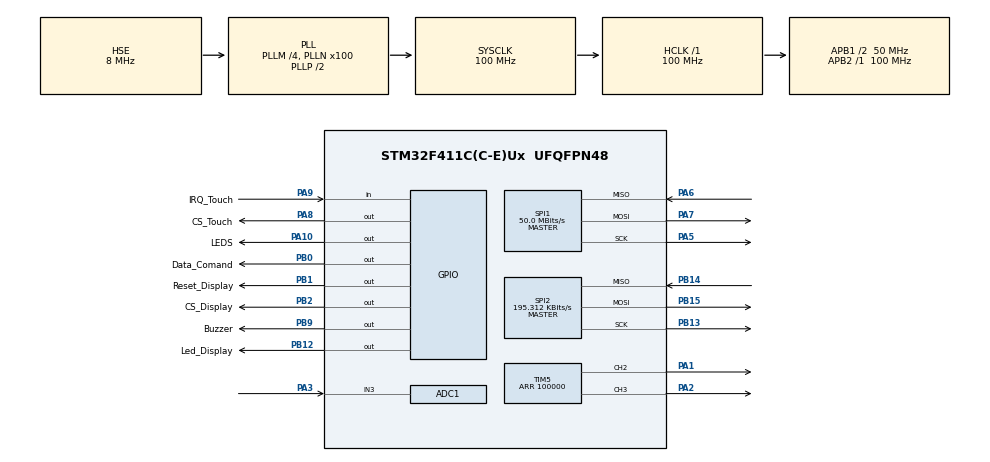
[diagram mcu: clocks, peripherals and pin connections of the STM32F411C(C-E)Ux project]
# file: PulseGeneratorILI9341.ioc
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ADC1.Channel-0\#ChannelRegularConversion=ADC_CHANNEL_3
ADC1.ClockPrescaler=ADC_CLOCK_SYNC_PCLK_DIV6
ADC1.ContinuousConvMode=ENABLE
ADC1.DMAContinuousRequests=ENABLE
ADC1.ExternalTrigConv=ADC_SOFTWARE_START
ADC1.InjNumberOfConversion=0
ADC1.NbrOfConversion=1
ADC1.NbrOfConversionFlag=1
ADC1.Rank-0\#ChannelRegularConversion=1
ADC1.SamplingTime-0\#ChannelRegularConversion=ADC_SAMPLETIME_480CYCLES
ADC1.master=1
Dma.ADC1.0.Direction=DMA_PERIPH_TO_MEMORY
Dma.ADC1.0.FIFOMode=DMA_FIFOMODE_DISABLE
Dma.ADC1.0.Instance=DMA2_Stream0
Dma.ADC1.0.MemDataAlignment=DMA_MDATAALIGN_HALFWORD
Dma.ADC1.0.MemInc=DMA_MINC_ENABLE
Dma.ADC1.0.Mode=DMA_CIRCULAR
Dma.ADC1.0.PeriphDataAlignment=DMA_PDATAALIGN_HALFWORD
Dma.ADC1.0.PeriphInc=DMA_PINC_DISABLE
Dma.ADC1.0.Priority=DMA_PRIORITY_LOW
Dma.Request0=ADC1
Mcu.Family=STM32F4
Mcu.Name=STM32F411C(C-E)Ux
Mcu.Package=UFQFPN48
NVIC.PriorityGroup=NVIC_PRIORITYGROUP_4
NVIC.TIM5_IRQn=true\:0\:0\:false\:false\:true\:true\:true\:true
PA1.Signal=S_TIM5_CH2
PA10.GPIO_Label=LEDS
PA10.Signal=GPIO_Output
PA13.Mode=Serial_Wire
PA13.Signal=SYS_JTMS-SWDIO
PA14.Mode=Serial_Wire
PA14.Signal=SYS_JTCK-SWCLK
PA2.Signal=S_TIM5_CH3
PA3.Signal=ADCx_IN3
PA5.Mode=Full_Duplex_Master
PA5.Signal=SPI1_SCK
PA6.Mode=Full_Duplex_Master
PA6.Signal=SPI1_MISO
PA7.Mode=Full_Duplex_Master
PA7.Signal=SPI1_MOSI
PA8.GPIO_Label=CS_Touch
PA8.Signal=GPIO_Output
PA9.GPIO_Label=IRQ_Touch
PA9.Signal=GPIO_Input
PB0.GPIO_Label=Data_Comand
PB0.Signal=GPIO_Output
PB1.GPIO_Label=Reset_Display
PB1.Signal=GPIO_Output
PB12.GPIO_Label=Led_Display
PB12.Signal=GPIO_Output
PB13.Mode=Full_Duplex_Master
PB13.Signal=SPI2_SCK
PB14.Mode=Full_Duplex_Master
PB14.Signal=SPI2_MISO
PB15.Mode=Full_Duplex_Master
PB15.Signal=SPI2_MOSI
PB2.GPIO_Label=CS_Display
PB2.Signal=GPIO_Output
PB9.GPIO_Label=Buzzer
PB9.Signal=GPIO_Output
PH0\ -\ OSC_IN.Mode=HSE-External-Oscillator
PH0\ -\ OSC_IN.Signal=RCC_OSC_IN
PH1\ -\ OSC_OUT.Mode=HSE-External-Oscillator
PH1\ -\ OSC_OUT.Signal=RCC_OSC_OUT
ProjectManager.HeapSize=0x200
ProjectManager.StackSize=0x400
ProjectManager.TargetToolchain=STM32CubeIDE
RCC.48MHZClocksFreq_Value=50000000
RCC.AHBFreq_Value=100000000
RCC.APB1CLKDivider=RCC_HCLK_DIV2
RCC.APB1Freq_Value=50000000
RCC.APB1TimFreq_Value=100000000
RCC.APB2Freq_Value=100000000
RCC.APB2TimFreq_Value=100000000
RCC.CortexFreq_Value=100000000
RCC.HCLKFreq_Value=100000000
RCC.HSE_VALUE=8000000
RCC.HSI_VALUE=16000000
RCC.LSE_VALUE=32768
RCC.PLLM=4
RCC.PLLN=100
RCC.PLLSourceVirtual=RCC_PLLSOURCE_HSE
RCC.SYSCLKFreq_VALUE=100000000
RCC.SYSCLKSource=RCC_SYSCLKSOURCE_PLLCLK
RCC.VCOOutputFreq_Value=200000000
SH.ADCx_IN3.0=ADC1_IN3,IN3
SH.S_TIM5_CH2.0=TIM5_CH2,PWM Generation2 CH2
SH.S_TIM5_CH3.0=TIM5_CH3,PWM Generation3 CH3
SPI1.BaudRatePrescaler=SPI_BAUDRATEPRESCALER_2
SPI1.CalculateBaudRate=50.0 MBits/s
SPI1.Direction=SPI_DIRECTION_2LINES
SPI1.Mode=SPI_MODE_MASTER
SPI1.VirtualType=VM_MASTER
SPI2.BaudRatePrescaler=SPI_BAUDRATEPRESCALER_256
SPI2.CalculateBaudRate=195.312 KBits/s
SPI2.Direction=SPI_DIRECTION_2LINES
SPI2.Mode=SPI_MODE_MASTER
SPI2.VirtualType=VM_MASTER
TIM5.AutoReloadPreload=TIM_AUTORELOAD_PRELOAD_ENABLE
TIM5.Channel-PWM\ Generation2\ CH2=TIM_CHANNEL_2
TIM5.Channel-PWM\ Generation3\ CH3=TIM_CHANNEL_3
TIM5.Period=100000
TIM5.Pulse-PWM\ Generation2\ CH2=25000
TIM5.Pulse-PWM\ Generation3\ CH3=2100
TIM5.TIM_MasterSlaveMode=TIM_MASTERSLAVEMODE_DISABLE
board=custom

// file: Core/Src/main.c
/* USER CODE BEGIN Header */
/**
  ******************************************************************************
  * @file           : main.c
  * @brief          : Main program body
  ******************************************************************************
  * @attention
  *
  * Copyright (c) 2023 STMicroelectronics.
  * All rights reserved.
  *
  * This software is licensed under terms that can be found in the LICENSE file
  * in the root directory of this software component.
  * If no LICENSE file comes with this software, it is provided AS-IS.
  *
  ******************************************************************************
  */
/* USER CODE END Header */
#include "main.h"

ADC_HandleTypeDef hadc1;
DMA_HandleTypeDef hdma_adc1;

SPI_HandleTypeDef hspi1;
SPI_HandleTypeDef hspi2;

TIM_HandleTypeDef htim5;

/* USER CODE BEGIN PV */
uint16_t adcBuf [FILTRADC] = {0};
//uint32_t * ptrBuf = adcBuf;
/* USER CODE END PV */

void SystemClock_Config(void);
static void MX_GPIO_Init(void);
static void MX_DMA_Init(void);
static void MX_SPI1_Init(void);
static void MX_SPI2_Init(void);
static void MX_TIM5_Init(void);
static void MX_ADC1_Init(void);

/* USER CODE BEGIN 0 */

/*void HAL_GPIO_EXTI_Callback(uint16_t GPIO_Pin){
}*/

/* USER CODE END 0 */

int main(void)
{
  /* USER CODE BEGIN 1 */
  //SYSCFG->MEMRMP = 0x3;    // для запуска из SRAM
  /* USER CODE END 1 */

  /* MCU Configuration--------------------------------------------------------*/

  /* Reset of all peripherals, Initializes the Flash interface and the Systick. */
  HAL_Init();

  /* Configure the system clock */
  SystemClock_Config();

  /* Initialize all configured peripherals */
  MX_GPIO_Init();
  MX_DMA_Init();
  MX_SPI1_Init();
  MX_SPI2_Init();
  MX_TIM5_Init();
  MX_ADC1_Init();
  /* USER CODE BEGIN 2 */
  SET_BIT(TIM5->CCER, TIM_CCER_CC2E);                     // включим выходы таймера на ноги МК
  SET_BIT(TIM5->CCER, TIM_CCER_CC3E);                     // включим выходы таймера на ноги МК
  CLEAR_BIT(TIM5->CCMR1, TIM_CCMR1_OC2M);                 // очистим регистр
  CLEAR_BIT(TIM5->CCMR2, TIM_CCMR2_OC3M);                 // очистим регистр
  SET_BIT(TIM5->CCMR1, 0b100 << TIM_CCMR1_OC2M_Pos);      // ноль на выходе Force inactive level
  SET_BIT(TIM5->CCMR2, 0b100 << TIM_CCMR2_OC3M_Pos);      // ноль на выходе Force inactive level
  HAL_ADC_Start_DMA (&hadc1, (uint32_t *)adcBuf, FILTRADC);      // запустим АЦП
  doWork ();
  /* USER CODE END 2 */

  /* Infinite loop */
  /* USER CODE BEGIN WHILE */
  while (1)
  {
	  Work ();
    /* USER CODE END WHILE */

  }
}

void SystemClock_Config(void)
{
  RCC_OscInitTypeDef RCC_OscInitStruct = {0};
  RCC_ClkInitTypeDef RCC_ClkInitStruct = {0};

  /** Configure the main internal regulator output voltage
  */
  __HAL_RCC_PWR_CLK_ENABLE();
  __HAL_PWR_VOLTAGESCALING_CONFIG(PWR_REGULATOR_VOLTAGE_SCALE1);

  /** Initializes the RCC Oscillators according to the specified parameters
  * in the RCC_OscInitTypeDef structure.
  */
  RCC_OscInitStruct.OscillatorType = RCC_OSCILLATORTYPE_HSE;
  RCC_OscInitStruct.HSEState = RCC_HSE_ON;
  RCC_OscInitStruct.PLL.PLLState = RCC_PLL_ON;
  RCC_OscInitStruct.PLL.PLLSource = RCC_PLLSOURCE_HSE;
  RCC_OscInitStruct.PLL.PLLM = 4;
  RCC_OscInitStruct.PLL.PLLN = 100;
  RCC_OscInitStruct.PLL.PLLP = RCC_PLLP_DIV2;
  RCC_OscInitStruct.PLL.PLLQ = 4;
  if (HAL_RCC_OscConfig(&RCC_OscInitStruct) != HAL_OK)
  {
    Error_Handler();
  }

  /** Initializes the CPU, AHB and APB buses clocks
  */
  RCC_ClkInitStruct.ClockType = RCC_CLOCKTYPE_HCLK|RCC_CLOCKTYPE_SYSCLK
                              |RCC_CLOCKTYPE_PCLK1|RCC_CLOCKTYPE_PCLK2;
  RCC_ClkInitStruct.SYSCLKSource = RCC_SYSCLKSOURCE_PLLCLK;
  RCC_ClkInitStruct.AHBCLKDivider = RCC_SYSCLK_DIV1;
  RCC_ClkInitStruct.APB1CLKDivider = RCC_HCLK_DIV2;
  RCC_ClkInitStruct.APB2CLKDivider = RCC_HCLK_DIV1;

  if (HAL_RCC_ClockConfig(&RCC_ClkInitStruct, FLASH_LATENCY_3) != HAL_OK)
  {
    Error_Handler();
  }
}

static void MX_ADC1_Init(void)
{

  ADC_ChannelConfTypeDef sConfig = {0};

  /** Configure the global features of the ADC (Clock, Resolution, Data Alignment and number of conversion)
  */
  hadc1.Instance = ADC1;
  hadc1.Init.ClockPrescaler = ADC_CLOCK_SYNC_PCLK_DIV6;
  hadc1.Init.Resolution = ADC_RESOLUTION_12B;
  hadc1.Init.ScanConvMode = DISABLE;
  hadc1.Init.ContinuousConvMode = ENABLE;
  hadc1.Init.DiscontinuousConvMode = DISABLE;
  hadc1.Init.ExternalTrigConvEdge = ADC_EXTERNALTRIGCONVEDGE_NONE;
  hadc1.Init.ExternalTrigConv = ADC_SOFTWARE_START;
  hadc1.Init.DataAlign = ADC_DATAALIGN_RIGHT;
  hadc1.Init.NbrOfConversion = 1;
  hadc1.Init.DMAContinuousRequests = ENABLE;
  hadc1.Init.EOCSelection = ADC_EOC_SINGLE_CONV;
  if (HAL_ADC_Init(&hadc1) != HAL_OK)
  {
    Error_Handler();
  }

  /** Configure for the selected ADC regular channel its corresponding rank in the sequencer and its sample time.
  */
  sConfig.Channel = ADC_CHANNEL_3;
  sConfig.Rank = 1;
  sConfig.SamplingTime = ADC_SAMPLETIME_480CYCLES;
  if (HAL_ADC_ConfigChannel(&hadc1, &sConfig) != HAL_OK)
  {
    Error_Handler();
  }

}

static void MX_SPI1_Init(void)
{

  /* SPI1 parameter configuration*/
  hspi1.Instance = SPI1;
  hspi1.Init.Mode = SPI_MODE_MASTER;
  hspi1.Init.Direction = SPI_DIRECTION_2LINES;
  hspi1.Init.DataSize = SPI_DATASIZE_8BIT;
  hspi1.Init.CLKPolarity = SPI_POLARITY_LOW;
  hspi1.Init.CLKPhase = SPI_PHASE_1EDGE;
  hspi1.Init.NSS = SPI_NSS_SOFT;
  hspi1.Init.BaudRatePrescaler = SPI_BAUDRATEPRESCALER_2;
  hspi1.Init.FirstBit = SPI_FIRSTBIT_MSB;
  hspi1.Init.TIMode = SPI_TIMODE_DISABLE;
  hspi1.Init.CRCCalculation = SPI_CRCCALCULATION_DISABLE;
  hspi1.Init.CRCPolynomial = 10;
  if (HAL_SPI_Init(&hspi1) != HAL_OK)
  {
    Error_Handler();
  }

}

static void MX_SPI2_Init(void)
{

  /* SPI2 parameter configuration*/
  hspi2.Instance = SPI2;
  hspi2.Init.Mode = SPI_MODE_MASTER;
  hspi2.Init.Direction = SPI_DIRECTION_2LINES;
  hspi2.Init.DataSize = SPI_DATASIZE_8BIT;
  hspi2.Init.CLKPolarity = SPI_POLARITY_LOW;
  hspi2.Init.CLKPhase = SPI_PHASE_1EDGE;
  hspi2.Init.NSS = SPI_NSS_SOFT;
  hspi2.Init.BaudRatePrescaler = SPI_BAUDRATEPRESCALER_256;
  hspi2.Init.FirstBit = SPI_FIRSTBIT_MSB;
  hspi2.Init.TIMode = SPI_TIMODE_DISABLE;
  hspi2.Init.CRCCalculation = SPI_CRCCALCULATION_DISABLE;
  hspi2.Init.CRCPolynomial = 10;
  if (HAL_SPI_Init(&hspi2) != HAL_OK)
  {
    Error_Handler();
  }

}

static void MX_TIM5_Init(void)
{

  TIM_MasterConfigTypeDef sMasterConfig = {0};
  TIM_OC_InitTypeDef sConfigOC = {0};

  htim5.Instance = TIM5;
  htim5.Init.Prescaler = 0;
  htim5.Init.CounterMode = TIM_COUNTERMODE_UP;
  htim5.Init.Period = 100000;
  htim5.Init.ClockDivision = TIM_CLOCKDIVISION_DIV1;
  htim5.Init.AutoReloadPreload = TIM_AUTORELOAD_PRELOAD_ENABLE;
  if (HAL_TIM_PWM_Init(&htim5) != HAL_OK)
  {
    Error_Handler();
  }
  sMasterConfig.MasterOutputTrigger = TIM_TRGO_RESET;
  sMasterConfig.MasterSlaveMode = TIM_MASTERSLAVEMODE_DISABLE;
  if (HAL_TIMEx_MasterConfigSynchronization(&htim5, &sMasterConfig) != HAL_OK)
  {
    Error_Handler();
  }
  sConfigOC.OCMode = TIM_OCMODE_PWM1;
  sConfigOC.Pulse = 25000;
  sConfigOC.OCPolarity = TIM_OCPOLARITY_HIGH;
  sConfigOC.OCFastMode = TIM_OCFAST_DISABLE;
  if (HAL_TIM_PWM_ConfigChannel(&htim5, &sConfigOC, TIM_CHANNEL_2) != HAL_OK)
  {
    Error_Handler();
  }
  sConfigOC.Pulse = 2100;
  if (HAL_TIM_PWM_ConfigChannel(&htim5, &sConfigOC, TIM_CHANNEL_3) != HAL_OK)
  {
    Error_Handler();
  }
  HAL_TIM_MspPostInit(&htim5);

}

static void MX_DMA_Init(void)
{

  /* DMA controller clock enable */
  __HAL_RCC_DMA2_CLK_ENABLE();

}

static void MX_GPIO_Init(void)
{
  GPIO_InitTypeDef GPIO_InitStruct = {0};

  /* GPIO Ports Clock Enable */
  __HAL_RCC_GPIOH_CLK_ENABLE();
  __HAL_RCC_GPIOA_CLK_ENABLE();
  __HAL_RCC_GPIOB_CLK_ENABLE();

  /*Configure GPIO pin Output Level */
  HAL_GPIO_WritePin(GPIOB, Data_Comand_Pin|Reset_Display_Pin|CS_Display_Pin|Led_Display_Pin
                          |Buzzer_Pin, GPIO_PIN_RESET);

  /*Configure GPIO pin Output Level */
  HAL_GPIO_WritePin(GPIOA, CS_Touch_Pin|LEDS_Pin, GPIO_PIN_RESET);

  /*Configure GPIO pins : Data_Comand_Pin Reset_Display_Pin CS_Display_Pin Led_Display_Pin
                           Buzzer_Pin */
  GPIO_InitStruct.Pin = Data_Comand_Pin|Reset_Display_Pin|CS_Display_Pin|Led_Display_Pin
                          |Buzzer_Pin;
  GPIO_InitStruct.Mode = GPIO_MODE_OUTPUT_PP;
  GPIO_InitStruct.Pull = GPIO_NOPULL;
  GPIO_InitStruct.Speed = GPIO_SPEED_FREQ_LOW;
  HAL_GPIO_Init(GPIOB, &GPIO_InitStruct);

  /*Configure GPIO pins : CS_Touch_Pin LEDS_Pin */
  GPIO_InitStruct.Pin = CS_Touch_Pin|LEDS_Pin;
  GPIO_InitStruct.Mode = GPIO_MODE_OUTPUT_PP;
  GPIO_InitStruct.Pull = GPIO_NOPULL;
  GPIO_InitStruct.Speed = GPIO_SPEED_FREQ_LOW;
  HAL_GPIO_Init(GPIOA, &GPIO_InitStruct);

  /*Configure GPIO pin : IRQ_Touch_Pin */
  GPIO_InitStruct.Pin = IRQ_Touch_Pin;
  GPIO_InitStruct.Mode = GPIO_MODE_INPUT;
  GPIO_InitStruct.Pull = GPIO_NOPULL;
  HAL_GPIO_Init(IRQ_Touch_GPIO_Port, &GPIO_InitStruct);

}

void Error_Handler(void)
{
  __disable_irq();
  while (1)
  {
  }
}
